# N32G41x register map
Vendor: Nsingtech Ltd.; File version: 1.0
CPU: CM4 r0p1, little endian, no MPU, no FPU, 4 interrupt priority bits
Registers are 32-bit, read-write, reset 0x0 unless marked. A register's access mark holds for its fields unless they carry their own. Offsets are from the block's base; [hi:lo] are bit positions; {n}, {i} and the like mark numbered series; 'fields as' and 'values as' point back to an identical list.

## CAN — Controller Area Network
Base 0x40006400
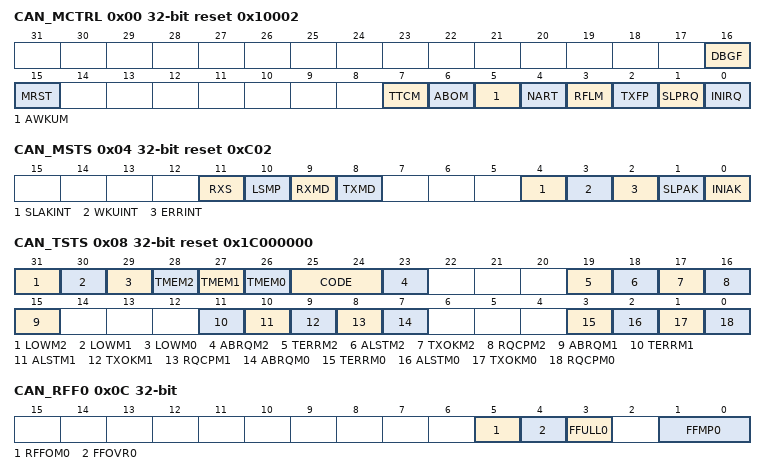
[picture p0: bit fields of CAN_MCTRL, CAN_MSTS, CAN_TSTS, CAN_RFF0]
0x00 CAN_MCTRL reset 0x10002 — CAN Master Control Register
  [16] DBGF — Debug freeze
  [15] MRST — CAN software master reset
  [7] TTCM — Time triggered communication mode
  [6] ABOM — Automatic bus-off management
  [5] AWKUM — Automatic wakeup mode
  [4] NART — No automatic retransmission
  [3] RFLM — Receive FIFO locked mode
  [2] TXFP — Transmit FIFO priority
  [1] SLPRQ — Sleep mode request
  [0] INIRQ — Initialization request
0x04 CAN_MSTS reset 0xC02 — CAN Master Status Register
  [11] RXS ro — CAN Rx signal
  [10] LSMP ro — Last sample point
  [9] RXMD ro — Receive mode
  [8] TXMD ro — Transmit mode
  [4] SLAKINT — Sleep acknowledge interrupt
  [3] WKUINT — Wakeup interrupt
  [2] ERRINT — Error interrupt
  [1] SLPAK ro — Sleep mode acknowledge
  [0] INIAK ro — Initialization acknowledge
0x08 CAN_TSTS reset 0x1C000000 — CAN Transmit Status Register
  [31] LOWM2 ro — Lowest priority flag mailbox2
  [30] LOWM1 ro — Lowest priority flag mailbox1
  [29] LOWM0 ro — Lowest priority flag mailbox0
  [28] TMEM2 ro — Transmit mailbox2 empty
  [27] TMEM1 ro — Transmit mailbox1 empty
  [26] TMEM0 ro — Transmit mailbox0 empty
  [25:24] CODE ro — Mailbox code
  [23] ABRQM2 — Abort request mailbox2
  [19] TERRM2 — Transmission error mailbox2
  [18] ALSTM2 — Arbitration lost mailbox2
  [17] TXOKM2 — Transmission OK mailbox2
  [16] RQCPM2 — Request completed mailbox2
  [15] ABRQM1 — Abort request mailbox1
  [11] TERRM1 — Transmission error mailbox1
  [10] ALSTM1 — Arbitration lost mailbox1
  [9] TXOKM1 — Transmission OK mailbox1
  [8] RQCPM1 — Request completed mailbox1
  [7] ABRQM0 — Abort request mailbox0
  [3] TERRM0 — Transmission error mailbox0
  [2] ALSTM0 — Arbitration lost mailbox0
  [1] TXOKM0 — Transmission OK mailbox0
  [0] RQCPM0 — Request completed mailbox0
0x0C CAN_RFF0 — CAN Receive FIFO0 Register
  [5] RFFOM0 — Release FIFO0 output mailbox
  [4] FFOVR0 — FIFO0 overrun
  [3] FFULL0 — FIFO0 full
  [1:0] FFMP0 ro — FIFO0 message pending
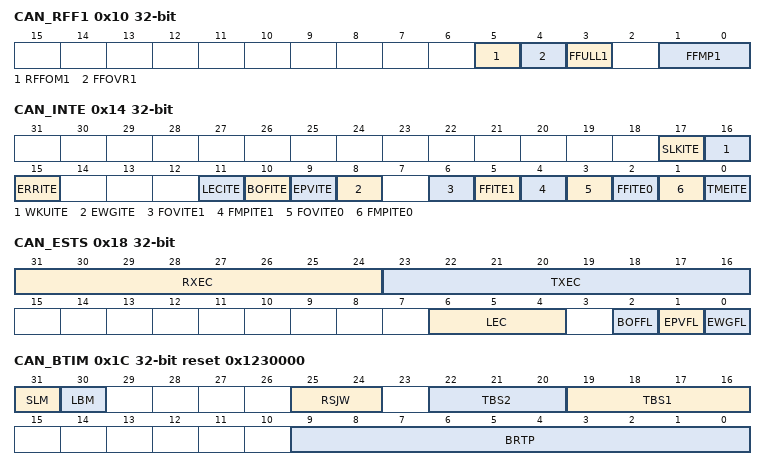
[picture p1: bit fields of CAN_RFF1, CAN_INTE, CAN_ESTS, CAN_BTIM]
0x10 CAN_RFF1 — CAN Receive FIFO1 Register
  [5] RFFOM1 — Release FIFO1 output mailbox
  [4] FFOVR1 — FIFO1 overrun
  [3] FFULL1 — FIFO1 full
  [1:0] FFMP1 ro — FIFO1 message pending
0x14 CAN_INTE — CAN Interrupt Enable Register
  [17] SLKITE — Sleep interrupt enable
  [16] WKUITE — Wakeup interrupt enable
  [15] ERRITE — Error interrupt enable
  [11] LECITE — Last error code interrupt enable
  [10] BOFITE — Bus-off interrupt enable
  [9] EPVITE — Error passive interrupt enable
  [8] EWGITE — Error warning interrupt enable
  [6] FOVITE1 — FIFO1 overrun interrupt enable
  [5] FFITE1 — FIFO1 full interrupt enable
  [4] FMPITE1 — FIFO1 message pending interrupt enable
  [3] FOVITE0 — FIFO0 overrun interrupt enable
  [2] FFITE0 — FIFO0 full interrupt enable
  [1] FMPITE0 — FIFO0 message pending interrupt enable
  [0] TMEITE — Transmit mailbox empty interrupt enable
0x18 CAN_ESTS — CAN Error Status Register
  [31:24] RXEC ro — Receive error counter
  [23:16] TXEC ro — Transmit error counter lower 8 bits
  [6:4] LEC — Last error code
  [2] BOFFL ro — Bus-off flag
  [1] EPVFL ro — Error passive flag
  [0] EWGFL ro — Error warning flag
0x1C CAN_BTIM reset 0x1230000 — CAN Bit Timing Register
  [31] SLM — Silent mode debug
  [30] LBM — Loop back mode debug
  [25:24] RSJW — Resynchronization jump width
  [22:20] TBS2 — Time segment 2
  [19:16] TBS1 — Time segment 1
  [9:0] BRTP — Baud rate prescaler
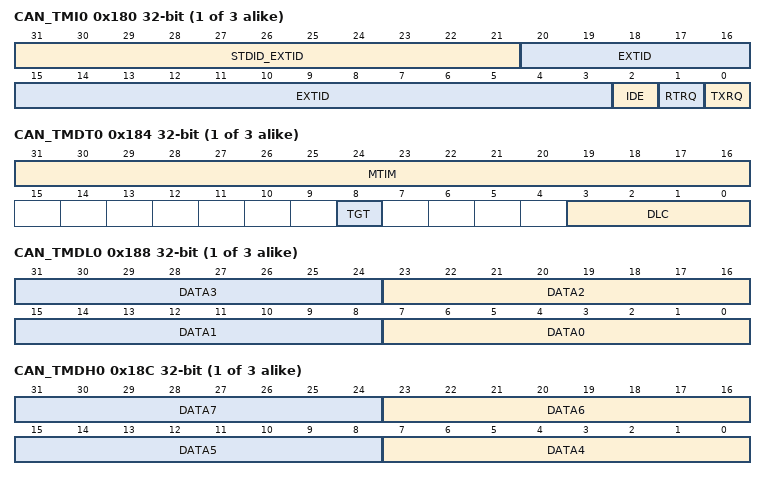
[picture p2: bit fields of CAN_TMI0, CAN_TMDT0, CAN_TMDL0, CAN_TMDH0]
{0x180+0x10*i} CAN_TMI{i} (i=0..2) — CAN Transmit Mailbox{i} Identifier Register
  [31:21] STDID_EXTID — Standard or extended identifier high part
  [20:3] EXTID — Extended identifier low part
  [2] IDE — Identifier extension
  [1] RTRQ — Remote transmission request
  [0] TXRQ — Transmit mailbox request
{0x184+0x10*i} CAN_TMDT{i} (i=0..2) — CAN Transmit Mailbox{i} Data Length Timestamp Register
  [31:16] MTIM — Message time stamp
  [8] TGT — Transmit global time
  [3:0] DLC — Data length code
{0x188+0x10*i} CAN_TMDL{i} (i=0..2) — CAN Transmit Mailbox{i} Low Data Register
  [8n+7:8n] DATA{n} (n=0..3) — Data byte{n}
{0x18C+0x10*i} CAN_TMDH{i} (i=0..2) — CAN Transmit Mailbox{i} High Data Register
  [8n-25:8n-32] DATA{n} (n=4..7) — Data byte{n}
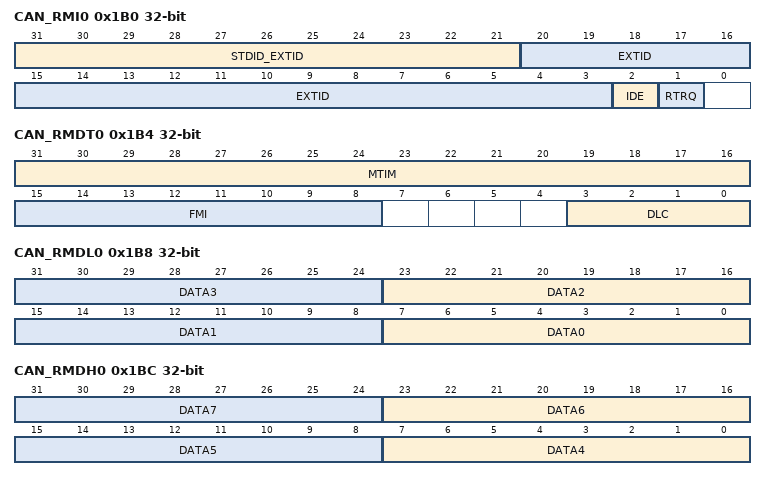
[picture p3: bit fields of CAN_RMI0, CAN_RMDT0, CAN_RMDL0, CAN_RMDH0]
0x1B0 CAN_RMI0 ro — CAN Receive FIFO0 Mailbox Identifier Register
  [31:21] STDID_EXTID — Standard or extended identifier high part
  [20:3] EXTID — Extended identifier low part
  [2] IDE — Identifier extension
  [1] RTRQ — Remote transmission request
0x1B4 CAN_RMDT0 ro — CAN Receive FIFO0 Mailbox Data Length Timestamp Register
  [31:16] MTIM — Message time stamp
  [15:8] FMI — Filter match index
  [3:0] DLC — Data length code
0x1B8 CAN_RMDL0 ro — CAN Receive FIFO0 Mailbox Low Data Register
  [8n+7:8n] DATA{n} (n=0..3) — Data byte{n}
0x1BC CAN_RMDH0 ro — CAN Receive FIFO0 Mailbox High Data Register
  [8n-25:8n-32] DATA{n} (n=4..7) — Data byte{n}
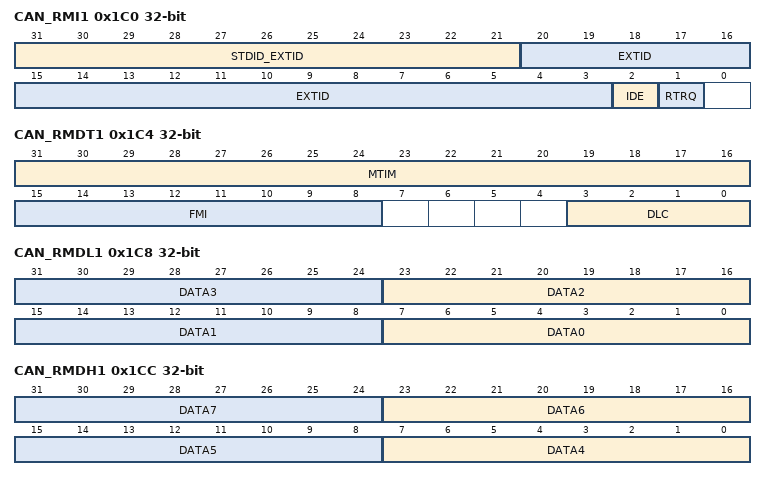
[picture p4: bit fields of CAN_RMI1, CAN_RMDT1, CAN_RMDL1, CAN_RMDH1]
0x1C0 CAN_RMI1 ro — CAN Receive FIFO1 Mailbox Identifier Register
  fields as CAN_RMI0
0x1C4 CAN_RMDT1 ro — CAN Receive FIFO1 Mailbox Data Length Timestamp Register
  fields as CAN_RMDT0
0x1C8 CAN_RMDL1 ro — CAN Receive FIFO1 Mailbox Low Data Register
  [8n+7:8n] DATA{n} (n=0..3) — Data byte{n}
0x1CC CAN_RMDH1 ro — CAN Receive FIFO1 Mailbox High Data Register
  [8n-25:8n-32] DATA{n} (n=4..7) — Data byte{n}
0x200 CAN_FMC reset 0x2A1C0E01 — CAN Filter Master Control Register
  [0] FINITM — Filter init mode
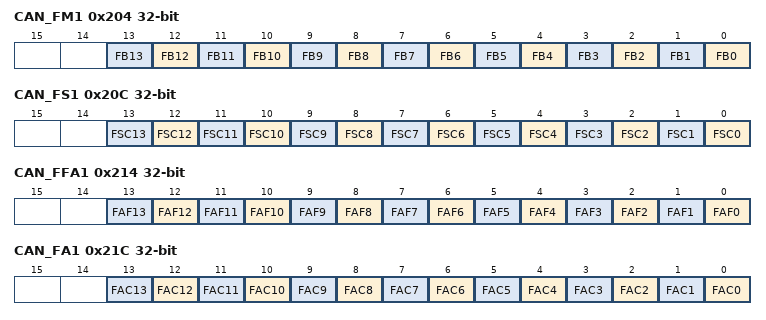
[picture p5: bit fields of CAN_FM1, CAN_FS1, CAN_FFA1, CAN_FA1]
0x204 CAN_FM1 — CAN Filter Mode Register
  [n] FB{n} (n=0..13) — Filter mode for group{n}
0x20C CAN_FS1 — CAN Filter Scale Register
  [n] FSC{n} (n=0..13) — Filter scale for group{n}
0x214 CAN_FFA1 — CAN Filter FIFO Assignment Register
  [n] FAF{n} (n=0..13) — Filter FIFO assignment for filter{n}
0x21C CAN_FA1 — CAN Filter Activation Register
  [n] FAC{n} (n=0..13) — Filter active for filter{n}
{0x240+8i} CAN_F{i}R1 (i=0..13) — CAN Filter{i} Register1
  [31:0] FBC — Filter bits identifier or mask
{0x244+8i} CAN_F{i}R2 (i=0..13) — CAN Filter{i} Register2
  [31:0] FBC — Filter bits identifier or mask
